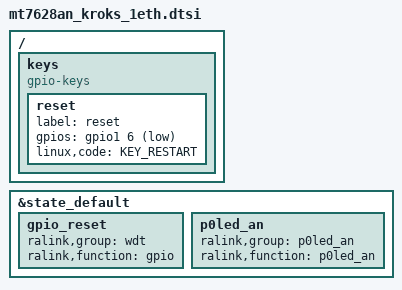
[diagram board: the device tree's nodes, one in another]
#include "mt7628an_kroks.dtsi"

#include <dt-bindings/input/input.h>
#include <dt-bindings/gpio/gpio.h>

/ {
	keys {
		compatible = "gpio-keys";

		reset {
			label = "reset";
			gpios = <&gpio1 6 GPIO_ACTIVE_LOW>;
			linux,code = <KEY_RESTART>;
		};
	};
};

&state_default {
	gpio_reset {
		ralink,group = "wdt";
		ralink,function = "gpio";
	};

	p0led_an {
		ralink,group = "p0led_an";
		ralink,function = "p0led_an";
	};
};
